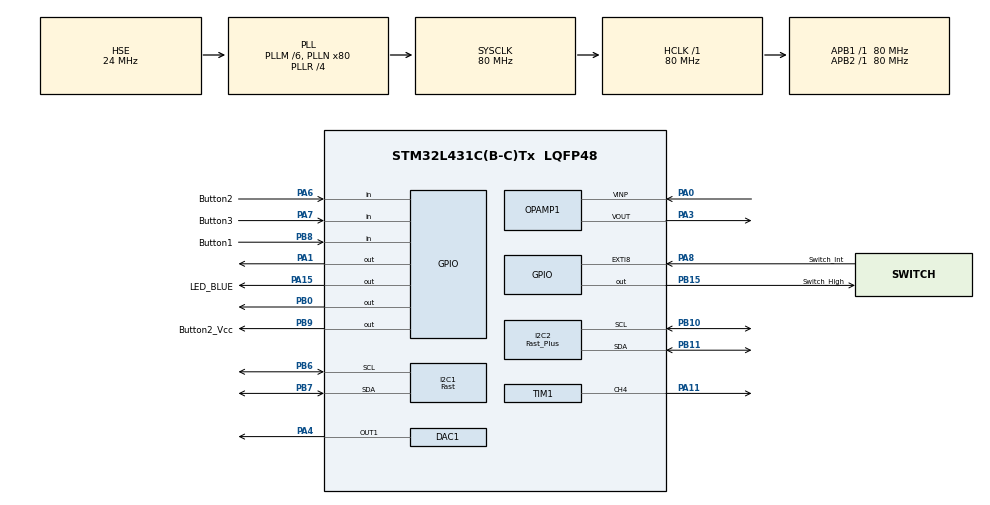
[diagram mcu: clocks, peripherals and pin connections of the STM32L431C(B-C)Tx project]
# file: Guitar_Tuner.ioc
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ADC1.Channel-7\#ChannelRegularConversion=ADC_CHANNEL_8
ADC1.DMAContinuousRequests=ENABLE
ADC1.EnableAnalogWatchDog1=false
ADC1.ExternalTrigConv=ADC_EXTERNALTRIG_T6_TRGO
ADC1.NbrOfConversion=1
ADC1.NbrOfConversionFlag=1
ADC1.OffsetNumber-7\#ChannelRegularConversion=ADC_OFFSET_NONE
ADC1.OversamplingMode=DISABLE
ADC1.Rank-7\#ChannelRegularConversion=1
ADC1.SamplingTime-7\#ChannelRegularConversion=ADC_SAMPLETIME_2CYCLES_5
ADC1.master=1
DAC1.DAC_Trigger-DAC_OUT1_ExtAndInt=DAC_TRIGGER_T7_TRGO
Dma.ADC1.0.Direction=DMA_PERIPH_TO_MEMORY
Dma.ADC1.0.Instance=DMA1_Channel1
Dma.ADC1.0.MemDataAlignment=DMA_MDATAALIGN_HALFWORD
Dma.ADC1.0.MemInc=DMA_MINC_ENABLE
Dma.ADC1.0.Mode=DMA_CIRCULAR
Dma.ADC1.0.PeriphDataAlignment=DMA_PDATAALIGN_HALFWORD
Dma.ADC1.0.PeriphInc=DMA_PINC_DISABLE
Dma.ADC1.0.Priority=DMA_PRIORITY_LOW
Dma.DAC_CH1.1.Direction=DMA_MEMORY_TO_PERIPH
Dma.DAC_CH1.1.Instance=DMA1_Channel3
Dma.DAC_CH1.1.MemDataAlignment=DMA_MDATAALIGN_WORD
Dma.DAC_CH1.1.MemInc=DMA_MINC_ENABLE
Dma.DAC_CH1.1.Mode=DMA_CIRCULAR
Dma.DAC_CH1.1.PeriphDataAlignment=DMA_PDATAALIGN_WORD
Dma.DAC_CH1.1.PeriphInc=DMA_PINC_DISABLE
Dma.DAC_CH1.1.Priority=DMA_PRIORITY_LOW
Dma.Request0=ADC1
Dma.Request1=DAC_CH1
I2C1.I2C_Speed_Mode=I2C_Fast
I2C1.Timing=0x00702991
I2C2.CustomTiming=Disabled
I2C2.I2C_Speed_Mode=I2C_Fast_Plus
I2C2.Timing=0x00300F33
Mcu.Family=STM32L4
Mcu.Name=STM32L431C(B-C)Tx
Mcu.Package=LQFP48
NVIC.DMA1_Channel1_IRQn=true\:0\:0\:false\:false\:true\:false\:true
NVIC.DMA1_Channel3_IRQn=true\:0\:0\:false\:false\:true\:false\:true
NVIC.EXTI9_5_IRQn=true\:1\:0\:true\:false\:true\:true\:true
NVIC.PriorityGroup=NVIC_PRIORITYGROUP_4
NVIC.TIM1_UP_TIM16_IRQn=true\:2\:0\:true\:false\:true\:true\:true
NVIC.TIM2_IRQn=true\:2\:0\:true\:false\:true\:true\:true
OPAMP1.PowerSupplyRange=OPAMP_POWERSUPPLY_HIGH
PA0.Mode=Follower
PA0.Signal=OPAMP1_VINP
PA1.Signal=GPIO_Output
PA11.Signal=S_TIM1_CH4
PA13\ (JTMS-SWDIO).Mode=Trace_Asynchronous_SW
PA13\ (JTMS-SWDIO).Signal=SYS_JTMS-SWDIO
PA14\ (JTCK-SWCLK).Mode=Trace_Asynchronous_SW
PA14\ (JTCK-SWCLK).Signal=SYS_JTCK-SWCLK
PA15\ (JTDI).GPIO_Label=LED_BLUE
PA15\ (JTDI).Signal=GPIO_Output
PA3.Mode=Follower
PA3.Signal=OPAMP1_VOUT
PA4.Signal=COMP_DAC11_group
PA6.GPIO_Label=Button2
PA6.Signal=GPIO_Input
PA7.GPIO_Label=Button3
PA7.Signal=GPIO_Input
PA8.GPIO_Label=Switch_Int
PA8.GPIO_ModeDefaultEXTI=GPIO_MODE_IT_RISING_FALLING
PA8.Signal=GPXTI8
PB0.Signal=GPIO_Output
PB10.Mode=I2C
PB10.Signal=I2C2_SCL
PB11.Mode=I2C
PB11.Signal=I2C2_SDA
PB15.GPIO_Label=Switch_High
PB15.PinState=GPIO_PIN_SET
PB15.Signal=GPIO_Output
PB3\ (JTDO-TRACESWO).Mode=Trace_Asynchronous_SW
PB3\ (JTDO-TRACESWO).Signal=SYS_JTDO-SWO
PB6.Mode=I2C
PB6.Signal=I2C1_SCL
PB7.Mode=I2C
PB7.Signal=I2C1_SDA
PB8.GPIO_Label=Button1
PB8.Signal=GPIO_Input
PB9.GPIO_Label=Button2_Vcc
PB9.Signal=GPIO_Output
PH0-OSC_IN\ (PH0).Mode=HSE-External-Oscillator
PH0-OSC_IN\ (PH0).Signal=RCC_OSC_IN
PH1-OSC_OUT\ (PH1).Mode=HSE-External-Oscillator
PH1-OSC_OUT\ (PH1).Signal=RCC_OSC_OUT
ProjectManager.HeapSize=0x200
ProjectManager.StackSize=0x400
ProjectManager.TargetToolchain=STM32CubeIDE
RCC.ADCFreq_Value=43000000
RCC.AHBFreq_Value=80000000
RCC.APB1Freq_Value=80000000
RCC.APB1TimFreq_Value=80000000
RCC.APB2Freq_Value=80000000
RCC.APB2TimFreq_Value=80000000
RCC.CortexFreq_Value=80000000
RCC.HCLKFreq_Value=80000000
RCC.HSE_VALUE=24000000
RCC.HSI48_VALUE=48000000
RCC.HSI_VALUE=16000000
RCC.LSE_VALUE=32768
RCC.MSI_VALUE=4000000
RCC.PLLM=6
RCC.PLLN=80
RCC.PLLR=RCC_PLLR_DIV4
RCC.PLLSAI1N=43
RCC.PLLSAI1R=RCC_PLLR_DIV4
RCC.PLLSourceVirtual=RCC_PLLSOURCE_HSE
RCC.SYSCLKFreq_VALUE=80000000
RCC.SYSCLKSource=RCC_SYSCLKSOURCE_PLLCLK
RCC.VCOOutputFreq_Value=320000000
SH.COMP_DAC11_group.0=DAC1_OUT1,DAC_OUT1_ExtAndInt
SH.S_TIM1_CH4.0=TIM1_CH4,PWM Generation4 CH4
TIM1.AutoReloadPreload=TIM_AUTORELOAD_PRELOAD_ENABLE
TIM1.Channel-PWM\ Generation4\ CH4=TIM_CHANNEL_4
TIM1.CounterMode=TIM_COUNTERMODE_UP
TIM1.Period=100
TIM1.Prescaler=2352
TIM1.Pulse-PWM\ Generation4\ CH4=50
TIM16.Period=4000 - 1
TIM16.Prescaler=20000
TIM2.AutoReloadPreload=TIM_AUTORELOAD_PRELOAD_ENABLE
TIM2.Period=8000 - 1
TIM2.Prescaler=10000- 1
TIM6.Period=2000 - 1
TIM6.TIM_MasterOutputTrigger=TIM_TRGO_UPDATE
TIM7.Period=10 - 1
TIM7.Prescaler=800 - 1
TIM7.TIM_MasterOutputTrigger=TIM_TRGO_UPDATE
VP_ADC1_OPAMP1_OUT.Mode=IN8-OPAMP1-Single-Ended
VP_TIM16_VS_ClockSourceINT.Mode=Enable_Timer
VP_TIM2_VS_ClockSourceINT.Mode=Internal
VP_TIM6_VS_ClockSourceINT.Mode=Enable_Timer
VP_TIM7_VS_ClockSourceINT.Mode=Enable_Timer
board=custom

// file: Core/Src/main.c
#include "main.h"
#include "arm_math.h"
#include <stdio.h>
#include <stdlib.h>
#include "oled_print.h"
#include "mpm.h"
#include "TJ_MPU6050.h"
#include "ssd1306.h"
#include <math.h>

// ARM IIR Filter Settings
#define NUM_IIR_STAGES 1
// ADC Defines
#define DC_BIAS 2280
#define BLOCK_SIZE 1024
#define FS 40000
#define THRESHOLD 600
#define NUM_STRINGS 6

#define E2 82.41
#define A2 110.0
#define D3 146.83
#define G3 196.0
#define B3 246.94
#define E4 329.63

#define E2_STRING_NUM 0
#define A2_STRING_NUM 1
#define D3_STRING_NUM 2
#define G3_STRING_NUM 3
#define B3_STRING_NUM 4
#define E4_STRING_NUM 5
#define U_FREQ_ERROR 20
#define L_FREQ_ERROR 20
#define TABLE_SIZE   5  //must be odd
#define TABLE_CENTRE TABLE_SIZE / 2
#define MIN_CORRECT 3

ADC_HandleTypeDef hadc1;
DMA_HandleTypeDef hdma_adc1;
DAC_HandleTypeDef hdac1;
DMA_HandleTypeDef hdma_dac_ch1;
I2C_HandleTypeDef hi2c1;
I2C_HandleTypeDef hi2c2;
OPAMP_HandleTypeDef hopamp1;

TIM_HandleTypeDef htim1;
TIM_HandleTypeDef htim2;
TIM_HandleTypeDef htim6;
TIM_HandleTypeDef htim7;
TIM_HandleTypeDef htim16;

int motor_wait = 0;
int callback_state = 0;
int Screenmode = 0;
int string_tracking = E2_STRING_NUM;
float32_t curr_target_string[NUM_STRINGS];
int mode = 0;
int correct_pitch_counter = 0;
void (*state)(); // Current state

// Pitch
float32_t pitch_table[TABLE_SIZE] = {0};
float32_t *table_pos_ptr = &pitch_table[0];

// ADC Variables
float32_t guitar_signal[BLOCK_SIZE];
uint16_t  adc_buff[2 * BLOCK_SIZE];
uint16_t *in_ptr;

// RawData_Def myAccelRaw, myGyroRaw;
ScaledData_Def myAccelScaled, myGyroScaled;
int screenflip = 0;

// ARM IIR Filter Variables
arm_biquad_casd_df1_inst_f32 iir_settings;
float iir_state[4];
static float iir_taps[5] = {
								0.997987115675119,
								-1.995974231350238,
								 0.997987115675119,
								 1.995970179642828,
								-0.995978283057647
							};

char * guitar_strings[] = { "E2", "A2", "D3", "G3", "B3", "E4" };

void SystemClock_Config(void);
static void MX_GPIO_Init(void);
static void MX_DMA_Init(void);
static void MX_TIM6_Init(void);
static void MX_OPAMP1_Init(void);
static void MX_ADC1_Init(void);
static void MX_I2C1_Init(void);
static void MX_DAC1_Init(void);
static void MX_TIM1_Init(void);
static void MX_I2C2_Init(void);
static void MX_TIM16_Init(void);
static void MX_TIM2_Init(void);
static void MX_TIM7_Init(void);
/* USER CODE BEGIN PFP */

void state_string_pitch(int UPP_LIM, int LOW_LIM, float32_t target_freq);
void state_get_pitch_error();
void state_tune_up_fine();
void state_tune_down_fine();
void state_tune_down_fast();
void state_tune_up_fast();
void state_get_pitch();
void state_tune();

void HAL_TIM_PeriodElapsedCallback(TIM_HandleTypeDef*htim)
{
	if(htim->Instance == TIM16)
	{

		MPU6050_Get_Accel_Scale(&myAccelScaled);
		MPU6050_Get_Gyro_Scale(&myGyroScaled);
		if (myAccelScaled.x > 0 && screenflip == 0)
		{
			ssd1306_Init1();
			screenflip = 1;
		} else if (myAccelScaled.x < 0 && screenflip == 1)
		{
			ssd1306_Init2();
			screenflip = 0;
		}

	} else if (htim->Instance == TIM2)
	{
		HAL_GPIO_WritePin(GPIOA, GPIO_PIN_1, GPIO_PIN_SET);
		HAL_Delay(50);
		HAL_GPIO_WritePin(GPIOA, GPIO_PIN_1, GPIO_PIN_RESET);
	}
}

void init_tunings()
{
	curr_target_string[0] = E2;
	curr_target_string[1] = A2;
	curr_target_string[2] = D3;
	curr_target_string[3] = G3;
	curr_target_string[4] = B3;
	curr_target_string[5] = E4;
}

void adc_to_guitar_signal(uint16_t *src, float32_t *guitar_signal)
{
	for(int i = 0; i < BLOCK_SIZE; i++)
	{
		guitar_signal[i] = (float32_t) src[i] - DC_BIAS;
	}
	arm_biquad_cascade_df1_f32(&iir_settings, guitar_signal, guitar_signal, BLOCK_SIZE);
}

void HAL_ADC_ConvHalfCpltCallback(ADC_HandleTypeDef* hadc1)
{
	in_ptr = &adc_buff[0];
	adc_to_guitar_signal(in_ptr, &guitar_signal[0]);

	float32_t *p  = &guitar_signal[0];
	for(int i = 0; i < BLOCK_SIZE; i++)
	{
		if(*p > THRESHOLD)
		{
			callback_state = 1;
			return;
		}
		p++;
	}
}

void HAL_ADC_ConvCpltCallback(ADC_HandleTypeDef* hadc1)
{
	in_ptr = &adc_buff[BLOCK_SIZE];
	adc_to_guitar_signal(in_ptr, &guitar_signal[0]);

	float32_t *p  = &guitar_signal[0];
	for(int i = 0; i < BLOCK_SIZE; i++)
	{
		if(*p > THRESHOLD)
		{
			callback_state = 1;
			return;
		}
		p++;
	}
}

int cmpfunc(const void * a, const void * b) {
  float32_t fa = *(const float32_t*) a;
  float32_t fb = *(const float32_t*) b;
  return (fa > fb) - (fa < fb);
}

void get_frequency(float32_t *signal, float32_t target_freq, float32_t *out_freq)
{
	if (callback_state == 1)
	{
		float32_t curr_freq = 0;
		mpm_mcleod_pitch_method_f32(&signal[0], &curr_freq);
		callback_state = 0;
		*out_freq = ceill(4 * curr_freq) / 4;
	}
}

float32_t get_error_in_cents(float32_t curr_frequency, float32_t target_frequency)
{
	float32_t error = 1200 * log2(curr_frequency / target_frequency);
	return round(error);
}

void toggle_motor_wait()
{
	if (motor_wait == 2)
	{
		motor_wait = 0;
	} else
	{
		motor_wait++;
	}
}

void state_tune_up_fine()
{
	int pulse_width = 46;
	__HAL_TIM_SET_COMPARE(&htim1, TIM_CHANNEL_4, pulse_width);
	HAL_Delay(100);
	pulse_width = 50;
	__HAL_TIM_SET_COMPARE(&htim1, TIM_CHANNEL_4, pulse_width);
	state = state_get_pitch;
}

void state_tune_up_fast()
{
	int pulse_width = 40;
	__HAL_TIM_SET_COMPARE(&htim1, TIM_CHANNEL_4, pulse_width);
	HAL_Delay(200);
	pulse_width = 50;
	__HAL_TIM_SET_COMPARE(&htim1, TIM_CHANNEL_4, pulse_width);
	HAL_Delay(100);
	motor_wait = 0;
	state = state_get_pitch;
}

void state_tune_down_fine()
{
	int pulse_width = 54;
	__HAL_TIM_SET_COMPARE(&htim1, TIM_CHANNEL_4, pulse_width);
	HAL_Delay(100);
	pulse_width = 50;
	__HAL_TIM_SET_COMPARE(&htim1, TIM_CHANNEL_4, pulse_width);
	state = state_get_pitch;
}

void state_tune_down_fast()
{
	int pulse_width = 64;
	__HAL_TIM_SET_COMPARE(&htim1, TIM_CHANNEL_4, pulse_width);
	HAL_Delay(200);
	pulse_width = 50;
	__HAL_TIM_SET_COMPARE(&htim1, TIM_CHANNEL_4, pulse_width);
	HAL_Delay(100);
	motor_wait = 0;
	state = state_get_pitch;
}

void iterate_table_pos()
{
	if(table_pos_ptr == &pitch_table[TABLE_SIZE - 1])
	{
		table_pos_ptr = &pitch_table[0];
	}else
	{
		table_pos_ptr++;
	}

}

float32_t  get_min_table()
{
	float32_t min = pitch_table[0];
	for (int i = 0; i < TABLE_SIZE; i++)
	{
		if(pitch_table[i] < min)
		{
			min = pitch_table[i];
		}
	}
	return min;
}

int init_table(int PITCH_U, int PITCH_L, float32_t target_freq)
{
	#define END TABLE_SIZE - 1

	if( pitch_table[END] < PITCH_L || pitch_table[END] > PITCH_U)
	{
		float32_t freq = 0;
		get_frequency(&guitar_signal[0], target_freq, &freq);
		if(PITCH_L < freq && freq < PITCH_U)
		{
			*table_pos_ptr = freq;
			iterate_table_pos();
			return 1;
		}
	}
	return 0;
}

void state_string_pitch(int UPP_LIM, int LOW_LIM, float32_t target_freq)
{
	if (correct_pitch_counter ==  MIN_CORRECT)
	{
		oled_clear_screen();
		char *str = "Next";
		oled_print_string(str);
		string_tracking++;
		correct_pitch_counter = 0;

		HAL_GPIO_WritePin(GPIOA, GPIO_PIN_1, GPIO_PIN_SET);
		HAL_Delay(50);
		HAL_GPIO_WritePin(GPIOA, GPIO_PIN_1, GPIO_PIN_RESET);
		HAL_Delay(200);
		HAL_GPIO_WritePin(GPIOA, GPIO_PIN_1, GPIO_PIN_SET);
		HAL_Delay(50);
		HAL_GPIO_WritePin(GPIOA, GPIO_PIN_1, GPIO_PIN_RESET);
		HAL_Delay(2000);
		return;
	}

	while(init_table(UPP_LIM, LOW_LIM, target_freq));

	float32_t freq = 0;
	get_frequency(&guitar_signal[0], target_freq, &freq);

	if(LOW_LIM < freq && freq < UPP_LIM)
	{
		*table_pos_ptr = freq;
		iterate_table_pos();
		float32_t m_freq = get_min_table();
		float32_t error = get_error_in_cents(m_freq, target_freq);

		oled_print_pitch_indicator_screen(guitar_strings[string_tracking], (int) error);

		if (motor_wait == 0)
		{
			if(error > 40) {
				state = state_tune_down_fast;
				correct_pitch_counter = 0;
			} else if (error > 7)
			{
				state = state_tune_down_fine;
				correct_pitch_counter = 0;
			}else if(error < -40.0)
			{

				state = state_tune_up_fast;
				correct_pitch_counter = 0;
			}else if(error < -7)
			{
				state = state_tune_up_fine;
				correct_pitch_counter = 0;
			} else
			{
				correct_pitch_counter++;
			}
		}
	}
	else
	{
		oled_clear_pitch_indicator_tick(guitar_strings[string_tracking]);
	}
	toggle_motor_wait();
}

void state_get_pitch()
{
	#define E2_U 100
	#define E2_L 55
	#define A2_U 140
	#define A2_L 85
	#define D3_U 190
	#define D3_L 115
	#define G3_U 230
	#define G3_L 155
	#define B3_U 320
	#define B3_L 205
	#define E4_U 350
	#define E4_L 305

	if (string_tracking == E2_STRING_NUM)
	{
		state_string_pitch(E2_U, E2_L, E2);

	} else if (string_tracking == A2_STRING_NUM)
	{
		state_string_pitch(A2_U, A2_L, A2);

	}else if (string_tracking == D3_STRING_NUM)
	{
		state_string_pitch(D3_U, D3_L, D3);

	}else if (string_tracking == G3_STRING_NUM)
	{
		state_string_pitch(G3_U, G3_L, G3);

	}else if (string_tracking == B3_STRING_NUM)
	{
		state_string_pitch(B3_U, B3_L, B3);

	}else if (string_tracking == E4_STRING_NUM)
	{
		state_string_pitch(E4_U, E4_L, E4);
	} else
	{
		string_tracking =  E2_STRING_NUM;
	}
}

void metronome(void)
{
	HAL_TIM_Base_Start_IT(&htim2);

	int bpm = 100;

	oled_timing_screen(bpm);
	ssd1306_UpdateScreen();

	while (1)
	{
		int exit = HAL_GPIO_ReadPin(Button1_GPIO_Port, Button1_Pin);

		if (exit == 1)
		{
			HAL_TIM_Base_Stop_IT(&htim2);
			return;
		}
		if (HAL_GPIO_ReadPin(Button2_GPIO_Port, Button2_Pin))
		{
			bpm++;
			oled_timing_screen(bpm);
			ssd1306_UpdateScreen();
		}
		if (HAL_GPIO_ReadPin(Button3_GPIO_Port, Button3_Pin))
		{
			bpm--;
			oled_timing_screen(bpm);
			ssd1306_UpdateScreen();
		}
		int pre_scalar = 10000 * 60 / bpm;
		__HAL_TIM_SET_PRESCALER(&htim2, pre_scalar);
	}
}

void get_sineval(uint32_t *sineval)
{
	for (int i=0; i<100; i++)
	{
		sineval[i] = 0.5 * ((sin(i*2*PI/100)+1)*(4096/2));
	}
}

void tone_gen(void)
{
	oled_tone_screen(100);
	HAL_TIM_Base_Start(&htim7);
	HAL_GPIO_WritePin(GPIOA, GPIO_PIN_15, GPIO_PIN_SET);
	HAL_Delay(300);

	uint32_t sineval[100];

	HAL_DAC_Start_DMA(&hdac1, DAC1_CHANNEL_1 , sineval, 100, DAC_ALIGN_12B_R);

	while (1)
	{
		int exit = HAL_GPIO_ReadPin(Button1_GPIO_Port, Button1_Pin);

		if (exit == 1)
		{
			HAL_DAC_Stop_DMA(&hdac1, DAC1_CHANNEL_1);
			//HAL_GPIO_WritePin(GPIOA, GPIO_PIN_15, GPIO_PIN_RESET);
			HAL_TIM_Base_Stop(&htim7);
			return;
		}
		if (HAL_GPIO_ReadPin(Button2_GPIO_Port, Button2_Pin))
		{

		}
		if (HAL_GPIO_ReadPin(Button3_GPIO_Port, Button3_Pin))
		{

		}

		get_sineval(&sineval[0]);

	}
}

int main(void)
{
	MPU_ConfigTypeDef myMpuConfig;

  HAL_Init();
  SystemClock_Config();

  MX_GPIO_Init();
  MX_DMA_Init();
  MX_TIM6_Init();
  MX_OPAMP1_Init();
  MX_ADC1_Init();
  MX_I2C1_Init();
  MX_DAC1_Init();
  MX_TIM1_Init();
  MX_I2C2_Init();
  MX_TIM16_Init();
  MX_TIM2_Init();
  MX_TIM7_Init();

	HAL_TIM_Base_Start(&htim6);
	HAL_TIM_PWM_Start(&htim1, TIM_CHANNEL_4);

	HAL_TIM_OC_Start(&htim6, TIM_CHANNEL_6);
	HAL_OPAMP_SelfCalibrate (&hopamp1);
	HAL_OPAMP_Start(&hopamp1);
	HAL_ADCEx_Calibration_Start(&hadc1, ADC_SINGLE_ENDED);
	HAL_ADC_Start_DMA(&hadc1, (uint32_t *)adc_buff, 2 * BLOCK_SIZE);
	arm_biquad_cascade_df1_init_f32(&iir_settings, NUM_IIR_STAGES, &iir_taps[0], &iir_state[0]);

	oled_init();
	init_tunings();

	MPU6050_Init(&hi2c1);
	myMpuConfig.Accel_Full_Scale = AFS_SEL_2g;
  myMpuConfig.CONFIG_DLPF = Internal_8MHz;
  myMpuConfig.ClockSource = DLPF_184A_188G_Hz;
  myMpuConfig.Gyro_Full_Scale = FS_SEL_500;
  myMpuConfig.Sleep_Mode_Bit = 0;
  MPU6050_Config(&myMpuConfig);

	HAL_TIM_Base_Start_IT(&htim16);

	state = state_get_pitch;

	HAL_GPIO_WritePin(GPIOB, GPIO_PIN_15, GPIO_PIN_SET);
	HAL_GPIO_WritePin(GPIOB, GPIO_PIN_0, GPIO_PIN_SET);
	HAL_GPIO_WritePin(GPIOB, GPIO_PIN_9, GPIO_PIN_SET);

	int counter = 0;
	while (1)
	{
		if (mode == 0)
		{
			int Button1_val = HAL_GPIO_ReadPin(Button1_GPIO_Port, Button1_Pin);
			int Button2_val = HAL_GPIO_ReadPin(Button2_GPIO_Port, Button2_Pin);
			int Button3_val = HAL_GPIO_ReadPin(Button3_GPIO_Port, Button3_Pin);

			if (Button2_val == 1 || Button3_val == 1)
			{
				if (counter == 0 )
				{
					oled_selection_screen();
					ssd1306_DrawRectangle(0, 36, 128,  58, 0);
					ssd1306_UpdateScreen();
					counter = 1;
					HAL_Delay(100);

				} else
				{
					oled_selection_screen();
					ssd1306_DrawRectangle(0, 8, 128,  30, 0);
					ssd1306_UpdateScreen();

					counter = 0;
					HAL_Delay(100);
				}
			}

			if (Button1_val == 1)
			{
				if (counter == 0)
				{

					tone_gen();
					oled_selection_screen();
					HAL_Delay(200);

			} else {

					metronome();
					oled_selection_screen();
					HAL_Delay(200);
				}
			}

		}else if (mode == 1)
		{
			//oled_timing_screen(100);
			state();
		}
	}
}

void SystemClock_Config(void)
{
  RCC_OscInitTypeDef RCC_OscInitStruct = {0};
  RCC_ClkInitTypeDef RCC_ClkInitStruct = {0};

  /** Configure the main internal regulator output voltage
  */
  if (HAL_PWREx_ControlVoltageScaling(PWR_REGULATOR_VOLTAGE_SCALE1) != HAL_OK)
  {
    Error_Handler();
  }
  /** Initializes the RCC Oscillators according to the specified parameters
  * in the RCC_OscInitTypeDef structure.
  */
  RCC_OscInitStruct.OscillatorType = RCC_OSCILLATORTYPE_HSE;
  RCC_OscInitStruct.HSEState = RCC_HSE_ON;
  RCC_OscInitStruct.PLL.PLLState = RCC_PLL_ON;
  RCC_OscInitStruct.PLL.PLLSource = RCC_PLLSOURCE_HSE;
  RCC_OscInitStruct.PLL.PLLM = 6;
  RCC_OscInitStruct.PLL.PLLN = 80;
  RCC_OscInitStruct.PLL.PLLP = RCC_PLLP_DIV7;
  RCC_OscInitStruct.PLL.PLLQ = RCC_PLLQ_DIV2;
  RCC_OscInitStruct.PLL.PLLR = RCC_PLLR_DIV4;
  if (HAL_RCC_OscConfig(&RCC_OscInitStruct) != HAL_OK)
  {
    Error_Handler();
  }
  /** Initializes the CPU, AHB and APB buses clocks
  */
  RCC_ClkInitStruct.ClockType = RCC_CLOCKTYPE_HCLK|RCC_CLOCKTYPE_SYSCLK
                              |RCC_CLOCKTYPE_PCLK1|RCC_CLOCKTYPE_PCLK2;
  RCC_ClkInitStruct.SYSCLKSource = RCC_SYSCLKSOURCE_PLLCLK;
  RCC_ClkInitStruct.AHBCLKDivider = RCC_SYSCLK_DIV1;
  RCC_ClkInitStruct.APB1CLKDivider = RCC_HCLK_DIV1;
  RCC_ClkInitStruct.APB2CLKDivider = RCC_HCLK_DIV1;

  if (HAL_RCC_ClockConfig(&RCC_ClkInitStruct, FLASH_LATENCY_4) != HAL_OK)
  {
    Error_Handler();
  }
}

static void MX_ADC1_Init(void)
{

  ADC_ChannelConfTypeDef sConfig = {0};

  /** Common config
  */
  hadc1.Instance = ADC1;
  hadc1.Init.ClockPrescaler = ADC_CLOCK_ASYNC_DIV1;
  hadc1.Init.Resolution = ADC_RESOLUTION_12B;
  hadc1.Init.DataAlign = ADC_DATAALIGN_RIGHT;
  hadc1.Init.ScanConvMode = ADC_SCAN_DISABLE;
  hadc1.Init.EOCSelection = ADC_EOC_SINGLE_CONV;
  hadc1.Init.LowPowerAutoWait = DISABLE;
  hadc1.Init.ContinuousConvMode = DISABLE;
  hadc1.Init.NbrOfConversion = 1;
  hadc1.Init.DiscontinuousConvMode = DISABLE;
  hadc1.Init.ExternalTrigConv = ADC_EXTERNALTRIG_T6_TRGO;
  hadc1.Init.ExternalTrigConvEdge = ADC_EXTERNALTRIGCONVEDGE_RISING;
  hadc1.Init.DMAContinuousRequests = ENABLE;
  hadc1.Init.Overrun = ADC_OVR_DATA_PRESERVED;
  hadc1.Init.OversamplingMode = DISABLE;
  if (HAL_ADC_Init(&hadc1) != HAL_OK)
  {
    Error_Handler();
  }
  /** Configure Regular Channel
  */
  sConfig.Channel = ADC_CHANNEL_8;
  sConfig.Rank = ADC_REGULAR_RANK_1;
  sConfig.SamplingTime = ADC_SAMPLETIME_2CYCLES_5;
  sConfig.SingleDiff = ADC_SINGLE_ENDED;
  sConfig.OffsetNumber = ADC_OFFSET_NONE;
  sConfig.Offset = 0;
  if (HAL_ADC_ConfigChannel(&hadc1, &sConfig) != HAL_OK)
  {
    Error_Handler();
  }

}

static void MX_DAC1_Init(void)
{

  DAC_ChannelConfTypeDef sConfig = {0};

  /** DAC Initialization
  */
  hdac1.Instance = DAC1;
  if (HAL_DAC_Init(&hdac1) != HAL_OK)
  {
    Error_Handler();
  }
  /** DAC channel OUT1 config
  */
  sConfig.DAC_SampleAndHold = DAC_SAMPLEANDHOLD_DISABLE;
  sConfig.DAC_Trigger = DAC_TRIGGER_T7_TRGO;
  sConfig.DAC_OutputBuffer = DAC_OUTPUTBUFFER_ENABLE;
  sConfig.DAC_ConnectOnChipPeripheral = DAC_CHIPCONNECT_ENABLE;
  sConfig.DAC_UserTrimming = DAC_TRIMMING_FACTORY;
  if (HAL_DAC_ConfigChannel(&hdac1, &sConfig, DAC_CHANNEL_1) != HAL_OK)
  {
    Error_Handler();
  }

}

static void MX_I2C1_Init(void)
{

  hi2c1.Instance = I2C1;
  hi2c1.Init.Timing = 0x00702991;
  hi2c1.Init.OwnAddress1 = 0;
  hi2c1.Init.AddressingMode = I2C_ADDRESSINGMODE_7BIT;
  hi2c1.Init.DualAddressMode = I2C_DUALADDRESS_DISABLE;
  hi2c1.Init.OwnAddress2 = 0;
  hi2c1.Init.OwnAddress2Masks = I2C_OA2_NOMASK;
  hi2c1.Init.GeneralCallMode = I2C_GENERALCALL_DISABLE;
  hi2c1.Init.NoStretchMode = I2C_NOSTRETCH_DISABLE;
  if (HAL_I2C_Init(&hi2c1) != HAL_OK)
  {
    Error_Handler();
  }
  /** Configure Analogue filter
  */
  if (HAL_I2CEx_ConfigAnalogFilter(&hi2c1, I2C_ANALOGFILTER_ENABLE) != HAL_OK)
  {
    Error_Handler();
  }
  /** Configure Digital filter
  */
  if (HAL_I2CEx_ConfigDigitalFilter(&hi2c1, 0) != HAL_OK)
  {
    Error_Handler();
  }

}

static void MX_I2C2_Init(void)
{

  hi2c2.Instance = I2C2;
  hi2c2.Init.Timing = 0x00300F33;
  hi2c2.Init.OwnAddress1 = 0;
  hi2c2.Init.AddressingMode = I2C_ADDRESSINGMODE_7BIT;
  hi2c2.Init.DualAddressMode = I2C_DUALADDRESS_DISABLE;
  hi2c2.Init.OwnAddress2 = 0;
  hi2c2.Init.OwnAddress2Masks = I2C_OA2_NOMASK;
  hi2c2.Init.GeneralCallMode = I2C_GENERALCALL_DISABLE;
  hi2c2.Init.NoStretchMode = I2C_NOSTRETCH_DISABLE;
  if (HAL_I2C_Init(&hi2c2) != HAL_OK)
  {
    Error_Handler();
  }
  /** Configure Analogue filter
  */
  if (HAL_I2CEx_ConfigAnalogFilter(&hi2c2, I2C_ANALOGFILTER_ENABLE) != HAL_OK)
  {
    Error_Handler();
  }
  /** Configure Digital filter
  */
  if (HAL_I2CEx_ConfigDigitalFilter(&hi2c2, 0) != HAL_OK)
  {
    Error_Handler();
  }
  /** I2C Fast mode Plus enable
  */
  HAL_I2CEx_EnableFastModePlus(I2C_FASTMODEPLUS_I2C2);

}

static void MX_OPAMP1_Init(void)
{

  hopamp1.Instance = OPAMP1;
  hopamp1.Init.PowerSupplyRange = OPAMP_POWERSUPPLY_HIGH;
  hopamp1.Init.Mode = OPAMP_FOLLOWER_MODE;
  hopamp1.Init.NonInvertingInput = OPAMP_NONINVERTINGINPUT_IO0;
  hopamp1.Init.PowerMode = OPAMP_POWERMODE_NORMALPOWER;
  hopamp1.Init.UserTrimming = OPAMP_TRIMMING_FACTORY;
  if (HAL_OPAMP_Init(&hopamp1) != HAL_OK)
  {
    Error_Handler();
  }

}

static void MX_TIM1_Init(void)
{

  TIM_MasterConfigTypeDef sMasterConfig = {0};
  TIM_OC_InitTypeDef sConfigOC = {0};
  TIM_BreakDeadTimeConfigTypeDef sBreakDeadTimeConfig = {0};

  htim1.Instance = TIM1;
  htim1.Init.Prescaler = 2352;
  htim1.Init.CounterMode = TIM_COUNTERMODE_UP;
  htim1.Init.Period = 100;
  htim1.Init.ClockDivision = TIM_CLOCKDIVISION_DIV1;
  htim1.Init.RepetitionCounter = 0;
  htim1.Init.AutoReloadPreload = TIM_AUTORELOAD_PRELOAD_ENABLE;
  if (HAL_TIM_PWM_Init(&htim1) != HAL_OK)
  {
    Error_Handler();
  }
  sMasterConfig.MasterOutputTrigger = TIM_TRGO_RESET;
  sMasterConfig.MasterOutputTrigger2 = TIM_TRGO2_RESET;
  sMasterConfig.MasterSlaveMode = TIM_MASTERSLAVEMODE_DISABLE;
  if (HAL_TIMEx_MasterConfigSynchronization(&htim1, &sMasterConfig) != HAL_OK)
  {
    Error_Handler();
  }
  sConfigOC.OCMode = TIM_OCMODE_PWM1;
  sConfigOC.Pulse = 50;
  sConfigOC.OCPolarity = TIM_OCPOLARITY_HIGH;
  sConfigOC.OCFastMode = TIM_OCFAST_DISABLE;
  sConfigOC.OCIdleState = TIM_OCIDLESTATE_RESET;
  sConfigOC.OCNIdleState = TIM_OCNIDLESTATE_RESET;
  if (HAL_TIM_PWM_ConfigChannel(&htim1, &sConfigOC, TIM_CHANNEL_4) != HAL_OK)
  {
    Error_Handler();
  }
  sBreakDeadTimeConfig.OffStateRunMode = TIM_OSSR_DISABLE;
  sBreakDeadTimeConfig.OffStateIDLEMode = TIM_OSSI_DISABLE;
  sBreakDeadTimeConfig.LockLevel = TIM_LOCKLEVEL_OFF;
  sBreakDeadTimeConfig.DeadTime = 0;
  sBreakDeadTimeConfig.BreakState = TIM_BREAK_DISABLE;
  sBreakDeadTimeConfig.BreakPolarity = TIM_BREAKPOLARITY_HIGH;
  sBreakDeadTimeConfig.BreakFilter = 0;
  sBreakDeadTimeConfig.Break2State = TIM_BREAK2_DISABLE;
  sBreakDeadTimeConfig.Break2Polarity = TIM_BREAK2POLARITY_HIGH;
  sBreakDeadTimeConfig.Break2Filter = 0;
  sBreakDeadTimeConfig.AutomaticOutput = TIM_AUTOMATICOUTPUT_DISABLE;
  if (HAL_TIMEx_ConfigBreakDeadTime(&htim1, &sBreakDeadTimeConfig) != HAL_OK)
  {
    Error_Handler();
  }
  HAL_TIM_MspPostInit(&htim1);

}

static void MX_TIM2_Init(void)
{

  TIM_ClockConfigTypeDef sClockSourceConfig = {0};
  TIM_MasterConfigTypeDef sMasterConfig = {0};

  htim2.Instance = TIM2;
  htim2.Init.Prescaler = 10000- 1;
  htim2.Init.CounterMode = TIM_COUNTERMODE_UP;
  htim2.Init.Period = 8000 - 1;
  htim2.Init.ClockDivision = TIM_CLOCKDIVISION_DIV1;
  htim2.Init.AutoReloadPreload = TIM_AUTORELOAD_PRELOAD_ENABLE;
  if (HAL_TIM_Base_Init(&htim2) != HAL_OK)
  {
    Error_Handler();
  }
  sClockSourceConfig.ClockSource = TIM_CLOCKSOURCE_INTERNAL;
  if (HAL_TIM_ConfigClockSource(&htim2, &sClockSourceConfig) != HAL_OK)
  {
    Error_Handler();
  }
  sMasterConfig.MasterOutputTrigger = TIM_TRGO_RESET;
  sMasterConfig.MasterSlaveMode = TIM_MASTERSLAVEMODE_DISABLE;
  if (HAL_TIMEx_MasterConfigSynchronization(&htim2, &sMasterConfig) != HAL_OK)
  {
    Error_Handler();
  }

}

static void MX_TIM6_Init(void)
{

  TIM_MasterConfigTypeDef sMasterConfig = {0};

  htim6.Instance = TIM6;
  htim6.Init.Prescaler = 0;
  htim6.Init.CounterMode = TIM_COUNTERMODE_UP;
  htim6.Init.Period = 2000 - 1;
  htim6.Init.AutoReloadPreload = TIM_AUTORELOAD_PRELOAD_DISABLE;
  if (HAL_TIM_Base_Init(&htim6) != HAL_OK)
  {
    Error_Handler();
  }
  sMasterConfig.MasterOutputTrigger = TIM_TRGO_UPDATE;
  sMasterConfig.MasterSlaveMode = TIM_MASTERSLAVEMODE_DISABLE;
  if (HAL_TIMEx_MasterConfigSynchronization(&htim6, &sMasterConfig) != HAL_OK)
  {
    Error_Handler();
  }

}

static void MX_TIM7_Init(void)
{

  TIM_MasterConfigTypeDef sMasterConfig = {0};

  htim7.Instance = TIM7;
  htim7.Init.Prescaler = 800 - 1;
  htim7.Init.CounterMode = TIM_COUNTERMODE_UP;
  htim7.Init.Period = 10 - 1;
  htim7.Init.AutoReloadPreload = TIM_AUTORELOAD_PRELOAD_DISABLE;
  if (HAL_TIM_Base_Init(&htim7) != HAL_OK)
  {
    Error_Handler();
  }
  sMasterConfig.MasterOutputTrigger = TIM_TRGO_UPDATE;
  sMasterConfig.MasterSlaveMode = TIM_MASTERSLAVEMODE_DISABLE;
  if (HAL_TIMEx_MasterConfigSynchronization(&htim7, &sMasterConfig) != HAL_OK)
  {
    Error_Handler();
  }

}

static void MX_TIM16_Init(void)
{

  htim16.Instance = TIM16;
  htim16.Init.Prescaler = 20000;
  htim16.Init.CounterMode = TIM_COUNTERMODE_UP;
  htim16.Init.Period = 4000 - 1;
  htim16.Init.ClockDivision = TIM_CLOCKDIVISION_DIV1;
  htim16.Init.RepetitionCounter = 0;
  htim16.Init.AutoReloadPreload = TIM_AUTORELOAD_PRELOAD_DISABLE;
  if (HAL_TIM_Base_Init(&htim16) != HAL_OK)
  {
    Error_Handler();
  }

}

static void MX_DMA_Init(void)
{

  /* DMA controller clock enable */
  __HAL_RCC_DMA1_CLK_ENABLE();

  /* DMA interrupt init */
  /* DMA1_Channel1_IRQn interrupt configuration */
  HAL_NVIC_SetPriority(DMA1_Channel1_IRQn, 0, 0);
  HAL_NVIC_EnableIRQ(DMA1_Channel1_IRQn);
  /* DMA1_Channel3_IRQn interrupt configuration */
  HAL_NVIC_SetPriority(DMA1_Channel3_IRQn, 0, 0);
  HAL_NVIC_EnableIRQ(DMA1_Channel3_IRQn);

}

static void MX_GPIO_Init(void)
{
  GPIO_InitTypeDef GPIO_InitStruct = {0};

  /* GPIO Ports Clock Enable */
  __HAL_RCC_GPIOH_CLK_ENABLE();
  __HAL_RCC_GPIOA_CLK_ENABLE();
  __HAL_RCC_GPIOB_CLK_ENABLE();

  /*Configure GPIO pin Output Level */
  HAL_GPIO_WritePin(GPIOA, GPIO_PIN_1|LED_BLUE_Pin, GPIO_PIN_RESET);

  /*Configure GPIO pin Output Level */
  HAL_GPIO_WritePin(GPIOB, GPIO_PIN_0|Button2_Vcc_Pin, GPIO_PIN_RESET);

  /*Configure GPIO pin Output Level */
  HAL_GPIO_WritePin(Switch_High_GPIO_Port, Switch_High_Pin, GPIO_PIN_SET);

  /*Configure GPIO pins : PA1 LED_BLUE_Pin */
  GPIO_InitStruct.Pin = GPIO_PIN_1|LED_BLUE_Pin;
  GPIO_InitStruct.Mode = GPIO_MODE_OUTPUT_PP;
  GPIO_InitStruct.Pull = GPIO_NOPULL;
  GPIO_InitStruct.Speed = GPIO_SPEED_FREQ_LOW;
  HAL_GPIO_Init(GPIOA, &GPIO_InitStruct);

  /*Configure GPIO pins : Button2_Pin Button3_Pin */
  GPIO_InitStruct.Pin = Button2_Pin|Button3_Pin;
  GPIO_InitStruct.Mode = GPIO_MODE_INPUT;
  GPIO_InitStruct.Pull = GPIO_NOPULL;
  HAL_GPIO_Init(GPIOA, &GPIO_InitStruct);

  /*Configure GPIO pins : PB0 Switch_High_Pin Button2_Vcc_Pin */
  GPIO_InitStruct.Pin = GPIO_PIN_0|Switch_High_Pin|Button2_Vcc_Pin;
  GPIO_InitStruct.Mode = GPIO_MODE_OUTPUT_PP;
  GPIO_InitStruct.Pull = GPIO_NOPULL;
  GPIO_InitStruct.Speed = GPIO_SPEED_FREQ_LOW;
  HAL_GPIO_Init(GPIOB, &GPIO_InitStruct);

  /*Configure GPIO pin : Switch_Int_Pin */
  GPIO_InitStruct.Pin = Switch_Int_Pin;
  GPIO_InitStruct.Mode = GPIO_MODE_IT_RISING_FALLING;
  GPIO_InitStruct.Pull = GPIO_NOPULL;
  HAL_GPIO_Init(Switch_Int_GPIO_Port, &GPIO_InitStruct);

  /*Configure GPIO pin : Button1_Pin */
  GPIO_InitStruct.Pin = Button1_Pin;
  GPIO_InitStruct.Mode = GPIO_MODE_INPUT;
  GPIO_InitStruct.Pull = GPIO_NOPULL;
  HAL_GPIO_Init(Button1_GPIO_Port, &GPIO_InitStruct);

  /* EXTI interrupt init*/
  HAL_NVIC_SetPriority(EXTI9_5_IRQn, 1, 0);
  HAL_NVIC_EnableIRQ(EXTI9_5_IRQn);

}

/* USER CODE BEGIN 4 */

void HAL_GPIO_EXTI_Callback(uint16_t GPIO_Pin)
{

	Screenmode = HAL_GPIO_ReadPin(GPIOA, Switch_Int_Pin);

	if (Screenmode == 0)
	{
		oled_selection_screen();
		mode = 0;

	} else
	{
		oled_clear_screen();
		mode = 1;
		char *s = "Tuning";
		oled_print_string(s);
		HAL_Delay(2000);
		oled_clear_screen();

	}

}

/* USER CODE END 4 */

void Error_Handler(void)
{
	__disable_irq();
	while (1)
	{
	}
}
